VERSION "GRC26 combined CAN database v0.1"

NS_ :

BS_:

BU_: MaxxECU AeroProbe ImuGps RemoteLogger Dash

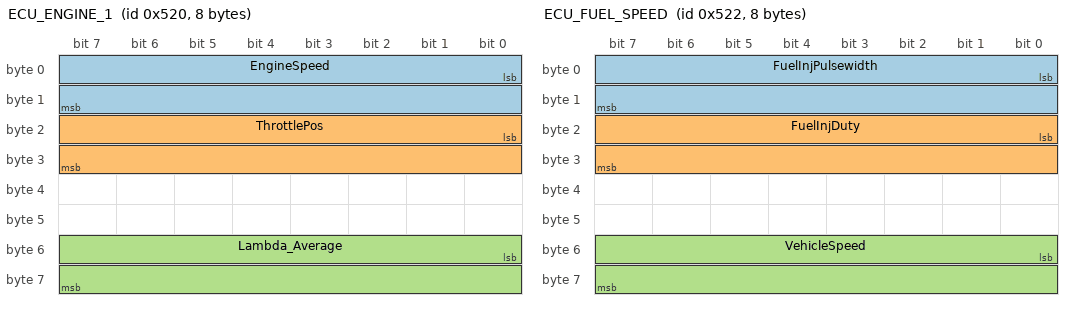
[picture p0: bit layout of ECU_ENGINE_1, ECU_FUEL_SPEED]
BO_ 1312 ECU_ENGINE_1: 8 MaxxECU
 SG_ EngineSpeed : 0|16@1+ (1,0) [0|65535] "rpm" Dash,RemoteLogger
 SG_ ThrottlePos : 16|16@1+ (0.1,0) [0|100] "%" Dash,RemoteLogger
 SG_ Lambda_Average : 48|16@1+ (0.001,0) [0|65.535] "lambda" Dash,RemoteLogger

BO_ 1313 ECU_LAMBDA: 8 MaxxECU
 SG_ Lambda_A : 0|16@1+ (0.001,0) [0|65.535] "lambda" RemoteLogger
 SG_ Lambda_B : 16|16@1+ (0.001,0) [0|65.535] "lambda" RemoteLogger

BO_ 1314 ECU_FUEL_SPEED: 8 MaxxECU
 SG_ FuelInjPulsewidth : 0|16@1+ (0.01,0) [0|655.35] "ms" RemoteLogger
 SG_ FuelInjDuty : 16|16@1+ (0.1,0) [0|6553.5] "%" RemoteLogger
 SG_ VehicleSpeed : 48|16@1+ (0.1,0) [0|6553.5] "km/h" Dash,RemoteLogger

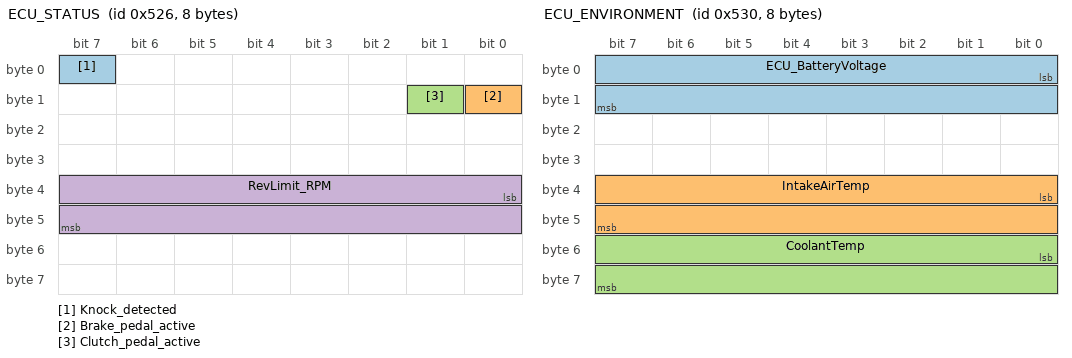
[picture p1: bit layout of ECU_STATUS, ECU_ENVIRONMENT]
BO_ 1318 ECU_STATUS: 8 MaxxECU
 SG_ Knock_detected : 7|1@1+ (1,0) [0|1] "" Dash,RemoteLogger
 SG_ Brake_pedal_active : 8|1@1+ (1,0) [0|1] "" Dash,RemoteLogger
 SG_ Clutch_pedal_active : 9|1@1+ (1,0) [0|1] "" Dash,RemoteLogger
 SG_ RevLimit_RPM : 32|16@1+ (1,0) [0|65535] "rpm" Dash,RemoteLogger

BO_ 1319 ECU_LAMBDA_TARGET: 8 MaxxECU
 SG_ Lambda_Target : 48|16@1- (0.001,0) [-32.768|32.767] "lambda" RemoteLogger

BO_ 1328 ECU_ENVIRONMENT: 8 MaxxECU
 SG_ ECU_BatteryVoltage : 0|16@1+ (0.01,0) [0|655.35] "V" Dash,RemoteLogger
 SG_ IntakeAirTemp : 32|16@1+ (0.1,0) [0|6553.5] "degC" Dash,RemoteLogger
 SG_ CoolantTemp : 48|16@1+ (0.1,0) [0|6553.5] "degC" Dash,RemoteLogger

BO_ 1334 ECU_GEAR: 8 MaxxECU
 SG_ GearPosn : 0|16@1+ (1,0) [0|65535] "" Dash,RemoteLogger

BO_ 1336 ECU_USER_CHANNELS_1: 8 MaxxECU
 SG_ User_Channel_1 : 0|16@1+ (0.1,0) [0|6553.5] "" Dash,RemoteLogger

BO_ 1536 AEROPROBE_PRESSURES: 8 AeroProbe
 SG_ AeroProbe_Pressure_1 : 0|16@1- (1,0) [-32768|32767] "Pa" RemoteLogger
 SG_ AeroProbe_Pressure_2 : 16|16@1- (1,0) [-32768|32767] "Pa" RemoteLogger

BO_ 1537 AEROPROBE_AMBIENT: 8 AeroProbe
 SG_ AeroProbe_AmbientTemp : 0|16@1- (0.01,0) [-327.68|327.67] "degC" RemoteLogger
 SG_ AeroProbe_AmbientPressure : 16|16@1+ (0.1,0) [0|6553.5] "hPa" RemoteLogger

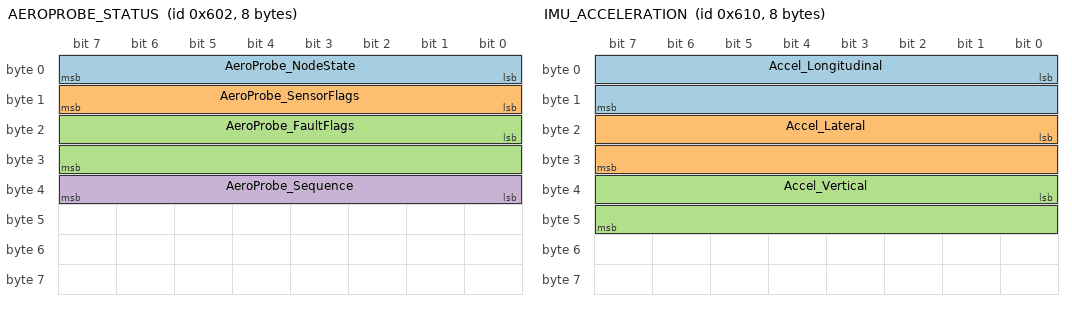
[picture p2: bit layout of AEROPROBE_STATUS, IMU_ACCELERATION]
BO_ 1538 AEROPROBE_STATUS: 8 AeroProbe
 SG_ AeroProbe_NodeState : 0|8@1+ (1,0) [0|255] "" RemoteLogger
 SG_ AeroProbe_SensorFlags : 8|8@1+ (1,0) [0|255] "" RemoteLogger
 SG_ AeroProbe_FaultFlags : 16|16@1+ (1,0) [0|65535] "" RemoteLogger
 SG_ AeroProbe_Sequence : 32|8@1+ (1,0) [0|255] "" RemoteLogger

BO_ 1552 IMU_ACCELERATION: 8 ImuGps
 SG_ Accel_Longitudinal : 0|16@1- (0.001,0) [-32.768|32.767] "g" RemoteLogger
 SG_ Accel_Lateral : 16|16@1- (0.001,0) [-32.768|32.767] "g" RemoteLogger
 SG_ Accel_Vertical : 32|16@1- (0.001,0) [-32.768|32.767] "g" RemoteLogger

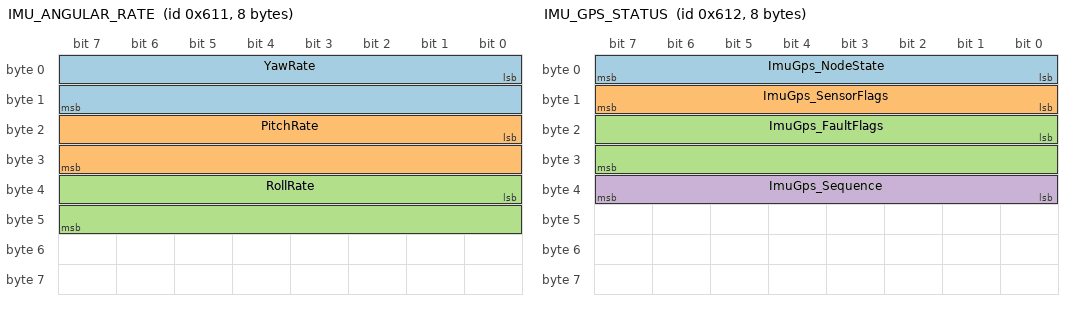
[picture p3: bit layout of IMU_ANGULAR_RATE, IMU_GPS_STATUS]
BO_ 1553 IMU_ANGULAR_RATE: 8 ImuGps
 SG_ YawRate : 0|16@1- (0.01,0) [-327.68|327.67] "deg/s" RemoteLogger
 SG_ PitchRate : 16|16@1- (0.01,0) [-327.68|327.67] "deg/s" RemoteLogger
 SG_ RollRate : 32|16@1- (0.01,0) [-327.68|327.67] "deg/s" RemoteLogger

BO_ 1554 IMU_GPS_STATUS: 8 ImuGps
 SG_ ImuGps_NodeState : 0|8@1+ (1,0) [0|255] "" RemoteLogger
 SG_ ImuGps_SensorFlags : 8|8@1+ (1,0) [0|255] "" RemoteLogger
 SG_ ImuGps_FaultFlags : 16|16@1+ (1,0) [0|65535] "" RemoteLogger
 SG_ ImuGps_Sequence : 32|8@1+ (1,0) [0|255] "" RemoteLogger

BO_ 1568 GPS_POSITION: 8 ImuGps
 SG_ GPS_Latitude : 0|32@1- (1e-07,0) [-214.7483648|214.7483647] "deg" RemoteLogger
 SG_ GPS_Longitude : 32|32@1- (1e-07,0) [-214.7483648|214.7483647] "deg" RemoteLogger

BO_ 1569 GPS_MOTION: 8 ImuGps
 SG_ GPS_GroundSpeed : 0|16@1+ (0.01,0) [0|655.35] "km/h" RemoteLogger
 SG_ GPS_Course : 16|16@1+ (0.01,0) [0|655.35] "deg" RemoteLogger

CM_ BU_ MaxxECU "Vendor protocol v1.3; selected signals match CAN_Signal_Checklist(1).xlsx On car selections.";
CM_ BO_ 1336 "User_Channel_1 must be named to its actual MTune assignment before vehicle use.";
CM_ BO_ 1536 "DLVR-L30D-E1BD differential-pressure telemetry.";
CM_ BO_ 1537 "BME680 ambient-temperature and pressure telemetry.";
CM_ BO_ 1538 "NodeState: 0=boot, 1=healthy, 2=degraded, 3=fault. SensorFlags and FaultFlags are node-owned bitmasks.";
CM_ BO_ 1554 "NodeState: 0=boot, 1=healthy, 2=degraded, 3=fault. SensorFlags and FaultFlags are node-owned bitmasks.";

VAL_ 1538 AeroProbe_NodeState 0 "Boot" 1 "Healthy" 2 "Degraded" 3 "Fault";
VAL_ 1554 ImuGps_NodeState 0 "Boot" 1 "Healthy" 2 "Degraded" 3 "Fault";
